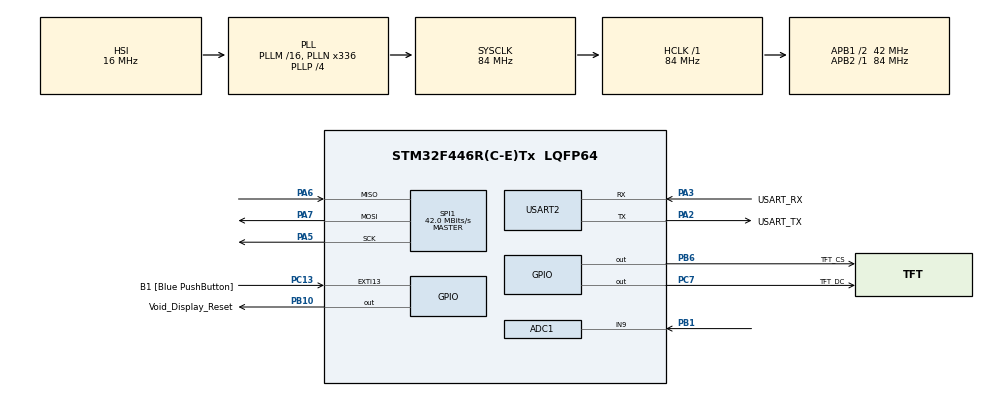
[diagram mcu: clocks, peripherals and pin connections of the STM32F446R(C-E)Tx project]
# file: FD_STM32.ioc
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ADC1.Channel-0\#ChannelRegularConversion=ADC_CHANNEL_9
ADC1.NbrOfConversionFlag=1
ADC1.Rank-0\#ChannelRegularConversion=1
ADC1.SamplingTime-0\#ChannelRegularConversion=ADC_SAMPLETIME_3CYCLES
ADC1.master=1
Dma.Request0=SPI1_TX
Dma.SPI1_TX.0.Direction=DMA_MEMORY_TO_PERIPH
Dma.SPI1_TX.0.FIFOMode=DMA_FIFOMODE_DISABLE
Dma.SPI1_TX.0.Instance=DMA2_Stream3
Dma.SPI1_TX.0.MemDataAlignment=DMA_MDATAALIGN_BYTE
Dma.SPI1_TX.0.MemInc=DMA_MINC_ENABLE
Dma.SPI1_TX.0.Mode=DMA_NORMAL
Dma.SPI1_TX.0.PeriphDataAlignment=DMA_PDATAALIGN_BYTE
Dma.SPI1_TX.0.PeriphInc=DMA_PINC_DISABLE
Dma.SPI1_TX.0.Priority=DMA_PRIORITY_LOW
Mcu.Family=STM32F4
Mcu.Name=STM32F446R(C-E)Tx
Mcu.Package=LQFP64
NVIC.DMA2_Stream3_IRQn=true\:0\:0\:false\:false\:true\:false\:true\:true
NVIC.PriorityGroup=NVIC_PRIORITYGROUP_0
NVIC.SPI1_IRQn=true\:0\:0\:false\:false\:true\:true\:true\:true
PA13.GPIO_Label=TMS
PA13.Mode=Serial_Wire
PA13.Signal=SYS_JTMS-SWDIO
PA14.GPIO_Label=TCK
PA14.Mode=Serial_Wire
PA14.Signal=SYS_JTCK-SWCLK
PA2.GPIO_Label=USART_TX
PA2.Mode=Asynchronous
PA2.Signal=USART2_TX
PA3.GPIO_Label=USART_RX
PA3.Mode=Asynchronous
PA3.Signal=USART2_RX
PA5.Mode=Full_Duplex_Master
PA5.Signal=SPI1_SCK
PA6.Mode=Full_Duplex_Master
PA6.Signal=SPI1_MISO
PA7.Mode=Full_Duplex_Master
PA7.Signal=SPI1_MOSI
PB1.Signal=ADCx_IN9
PB10.GPIO_Label=Void_Display_Reset
PB10.Signal=GPIO_Output
PB3.GPIO_Label=SWO
PB3.Signal=SYS_JTDO-SWO
PB6.GPIO_Label=TFT_CS
PB6.Signal=GPIO_Output
PC13.GPIO_Label=B1 [Blue PushButton]
PC13.GPIO_ModeDefaultEXTI=GPIO_MODE_IT_FALLING
PC13.Signal=GPXTI13
PC14-OSC32_IN.Mode=LSE-External-Oscillator
PC14-OSC32_IN.Signal=RCC_OSC32_IN
PC15-OSC32_OUT.Mode=LSE-External-Oscillator
PC15-OSC32_OUT.Signal=RCC_OSC32_OUT
PC7.GPIO_Label=TFT_DC
PC7.Signal=GPIO_Output
PH0-OSC_IN.Mode=HSE-External-Oscillator
PH0-OSC_IN.Signal=RCC_OSC_IN
PH1-OSC_OUT.Mode=HSE-External-Oscillator
PH1-OSC_OUT.Signal=RCC_OSC_OUT
ProjectManager.HeapSize=0x200
ProjectManager.StackSize=0x400
ProjectManager.TargetToolchain=MDK-ARM V5.32
RCC.48MHZClocksFreq_Value=84000000
RCC.AHBFreq_Value=84000000
RCC.APB1CLKDivider=RCC_HCLK_DIV2
RCC.APB1Freq_Value=42000000
RCC.APB1TimFreq_Value=84000000
RCC.APB2Freq_Value=84000000
RCC.APB2TimFreq_Value=84000000
RCC.CortexFreq_Value=84000000
RCC.FLatency-AdvancedSettings=FLASH_LATENCY_2
RCC.HCLKFreq_Value=84000000
RCC.HSE_VALUE=8000000
RCC.HSI_VALUE=16000000
RCC.PLLN=336
RCC.PLLP=RCC_PLLP_DIV4
RCC.SYSCLKFreq_VALUE=84000000
RCC.SYSCLKSource=RCC_SYSCLKSOURCE_PLLCLK
RCC.USBFreq_Value=168000000
RCC.VCOOutputFreq_Value=336000000
SH.ADCx_IN9.0=ADC1_IN9,IN9
SPI1.BaudRatePrescaler=SPI_BAUDRATEPRESCALER_2
SPI1.CalculateBaudRate=42.0 MBits/s
SPI1.Direction=SPI_DIRECTION_2LINES
SPI1.Mode=SPI_MODE_MASTER
SPI1.VirtualType=VM_MASTER
USART2.VirtualMode=VM_ASYNC
board=NUCLEO-F446RE

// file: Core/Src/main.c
/*
  laboratoire = 6
  groupe = 2
  date = 2024/octobre/11
  auteurs = Isaac Doré, Arnaud Gagner, Justin Botbol
  équipe = 05
*/

/* USER CODE BEGIN Header */
/**
 ******************************************************************************
 * @file           : main.c
 * @brief          : Main program body
 ******************************************************************************
 * @attention
 *
 * Copyright (c) 2023 STMicroelectronics.
 * All rights reserved.
 *
 * This software is licensed under terms that can be found in the LICENSE file
 * in the root directory of this software component.
 * If no LICENSE file comes with this software, it is provided AS-IS.
 *
 ******************************************************************************
 */
/* USER CODE END Header */
#include "main.h"
#include "adc.h"
#include "dma.h"
#include "gpio.h"
#include "spi.h"
#include "usart.h"

/* USER CODE BEGIN Includes */
#define ARM_MATH_CM4
#include "arm_math.h"

#include "ili9341.h"
#include "ili9341_gfx.h"
#include "stdio.h"
/* USER CODE END Includes */

/* USER CODE BEGIN PV */
ili9341_t *_screen;
arm_fir_instance_f32 fir_inst;
float tab_value[256];
float FFT_value[256];
float abs_value[128];
// matlab : a = fir1(15, 2*1.5/13.333)
float fir_tabs[16] = {-0.0028, -0.0059, -0.0092, -0.0011, 0.0333, 0.0967,
                      0.1698,  0.2193,  0.2193,  0.1698,  0.0967, 0.0333,
                      -0.0011, -0.0092, -0.0059, -0.0028};
float tab_fir_value[256];
float state_buf[16];
/* USER CODE END PV */;

void SystemClock_Config(void);

int main(void) {

  /* MCU Configuration--------------------------------------------------------*/

  /* Reset of all peripherals, Initializes the Flash interface and the Systick.
   */
  HAL_Init();

  /* Configure the system clock */
  SystemClock_Config();

  /* Initialize all configured peripherals */
  MX_GPIO_Init();
  MX_DMA_Init();
  MX_USART2_UART_Init();
  MX_SPI1_Init();
  MX_ADC1_Init();
  /* USER CODE BEGIN 2 */
  _screen = ili9341_new(&hspi1, Void_Display_Reset_GPIO_Port,
                        Void_Display_Reset_Pin, TFT_CS_GPIO_Port, TFT_CS_Pin,
                        TFT_DC_GPIO_Port, TFT_DC_Pin, isoLandscape, NULL, NULL,
                        NULL, NULL, itsNotSupported, itnNormalized);
  ili9341_fill_screen(_screen, ILI9341_BLACK);
  ili9341_text_attr_t text_attr = {&ili9341_font_11x18, ILI9341_WHITE,
                                   ILI9341_BLACK, 0, 0};

  arm_fir_init_f32(&fir_inst, 16, fir_tabs, state_buf, 1);
  /* USER CODE END 2 */

  /* Infinite loop */
  while (1) {
    float scale = 120.0 / 4095.0;
    for (int x = 0; x < 256; x++) {
      HAL_ADC_Start(&hadc1);
      HAL_ADC_PollForConversion(&hadc1, 75);
      float value = tab_value[x] = HAL_ADC_GetValue(&hadc1) * scale;
      char buffer[15] = {0};
      sprintf(buffer, "Value : %-6.2f", value);
      ili9341_draw_string(_screen, text_attr, buffer);
      // draw value
      ili9341_draw_pixel(_screen, ILI9341_BLUE, x, (int)(120 - value));

      arm_fir_f32(&fir_inst, tab_value + x, tab_fir_value + x, 1);

      // draw value through filter
      ili9341_draw_pixel(_screen, ILI9341_RED, x,
                         (int)(120 - tab_fir_value[x]));

      HAL_Delay(75);
    }
    arm_rfft_fast_instance_f32 fftInstance;
    arm_rfft_fast_init_f32(&fftInstance, 256);
    arm_rfft_fast_f32(&fftInstance, tab_fir_value, FFT_value, 0);
    arm_cmplx_mag_f32(FFT_value, abs_value, 128);
    float max_value;
    unsigned int max_index;
    arm_max_f32(abs_value, 128, &max_value, &max_index);
    scale = 120.0 / max_value;
    ili9341_fill_screen(_screen, ILI9341_BLACK);
    for (int x = 0; x < 128; x++) {
      float value = abs_value[x] * scale;
      ili9341_draw_line(_screen, ILI9341_RED, 2 * x, (int)(240 - value), 2 * x,
                        239);
      ili9341_draw_line(_screen, ILI9341_RED, 2 * x + 1, (int)(240 - value),
                        2 * x + 1, 239);
      char bufferFFT[20] = {0};
      sprintf(bufferFFT, "FFT : %-6.2f ", value);
      ili9341_draw_string(_screen, text_attr, bufferFFT);
    }
    HAL_Delay(5000);
  }
}

void SystemClock_Config(void) {
  RCC_OscInitTypeDef RCC_OscInitStruct = {0};
  RCC_ClkInitTypeDef RCC_ClkInitStruct = {0};

  /** Configure the main internal regulator output voltage
   */
  __HAL_RCC_PWR_CLK_ENABLE();
  __HAL_PWR_VOLTAGESCALING_CONFIG(PWR_REGULATOR_VOLTAGE_SCALE3);

  /** Initializes the RCC Oscillators according to the specified parameters
   * in the RCC_OscInitTypeDef structure.
   */
  RCC_OscInitStruct.OscillatorType = RCC_OSCILLATORTYPE_HSI;
  RCC_OscInitStruct.HSIState = RCC_HSI_ON;
  RCC_OscInitStruct.HSICalibrationValue = RCC_HSICALIBRATION_DEFAULT;
  RCC_OscInitStruct.PLL.PLLState = RCC_PLL_ON;
  RCC_OscInitStruct.PLL.PLLSource = RCC_PLLSOURCE_HSI;
  RCC_OscInitStruct.PLL.PLLM = 16;
  RCC_OscInitStruct.PLL.PLLN = 336;
  RCC_OscInitStruct.PLL.PLLP = RCC_PLLP_DIV4;
  RCC_OscInitStruct.PLL.PLLQ = 2;
  RCC_OscInitStruct.PLL.PLLR = 2;
  if (HAL_RCC_OscConfig(&RCC_OscInitStruct) != HAL_OK) {
    Error_Handler();
  }

  /** Initializes the CPU, AHB and APB buses clocks
   */
  RCC_ClkInitStruct.ClockType = RCC_CLOCKTYPE_HCLK | RCC_CLOCKTYPE_SYSCLK |
                                RCC_CLOCKTYPE_PCLK1 | RCC_CLOCKTYPE_PCLK2;
  RCC_ClkInitStruct.SYSCLKSource = RCC_SYSCLKSOURCE_PLLCLK;
  RCC_ClkInitStruct.AHBCLKDivider = RCC_SYSCLK_DIV1;
  RCC_ClkInitStruct.APB1CLKDivider = RCC_HCLK_DIV2;
  RCC_ClkInitStruct.APB2CLKDivider = RCC_HCLK_DIV1;

  if (HAL_RCC_ClockConfig(&RCC_ClkInitStruct, FLASH_LATENCY_2) != HAL_OK) {
    Error_Handler();
  }
}

void Error_Handler(void) {
  __disable_irq();
  while (1) {
  }
}

#ifdef USE_FULL_ASSERT
/**
 * @brief  Reports the name of the source file and the source line number
 *         where the assert_param error has occurred.
 * @param  file: pointer to the source file name
 * @param  line: assert_param error line source number
 * @retval None
 */
void assert_failed(uint8_t *file, uint32_t line) {
  /* USER CODE BEGIN 6 */
  /* User can add his own implementation to report the file name and line
     number,
     ex: printf("Wrong parameters value: file %s on line %d\r\n", file, line) */
  /* USER CODE END 6 */
}
#endif /* USE_FULL_ASSERT */
